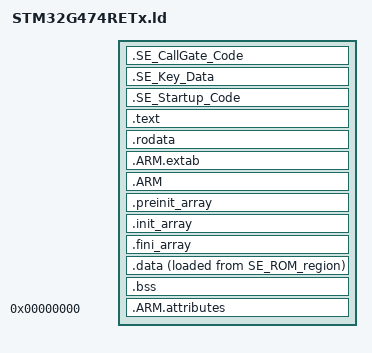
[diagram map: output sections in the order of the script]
/*
*****************************************************************************
**
**  File        : LinkerScript.ld
**
**  Abstract    : Linker script for STM32G474RETx Device with
**                512KByte FLASH, 128KByte RAM
**
**                Set heap size, stack size and stack location according
**                to application requirements.
**
**                Set memory bank area and size if external memory is used.
**
**  Target      : STMicroelectronics STM32
**
**
**  Distribution: The file is distributed as is, without any warranty
**                of any kind.
**
**  (c)Copyright Ac6.
**  You may use this file as-is or modify it according to the needs of your
**  project. Distribution of this file (unmodified or modified) is not
**  permitted. Ac6 permit registered System Workbench for MCU users the
**  rights to distribute the assembled, compiled & linked contents of this
**  file as part of an application binary file, provided that it is built
**  using the System Workbench for MCU toolchain.
**
*****************************************************************************
*/


/* Entry Point */
ENTRY(SE_CallGate)

/* Generate a link error if heap and stack don't fit into RAM */
_Min_Heap_Size = 0;      /* required amount of heap  */
_Min_Stack_Size = 0;     /* specific stack provided inside secured area */

INCLUDE mapping_fwimg.ld
INCLUDE mapping_sbsfu.ld

/* Define output sections */
SECTIONS
{
  .SE_CallGate_Code :
  {
    BYTE(0);           /* dummy byte to keep the callgate at 0x8000204 */
    BYTE(0);           /* dummy byte to keep the callgate at 0x8000204 */
    BYTE(0);           /* dummy byte to keep the callgate at 0x8000204 */
    BYTE(0);           /* dummy byte to keep the callgate at 0x8000204 */
    KEEP(*(.SE_CallGate_Code))
  } > SE_Entry_Secure_ROM_Region

  .SE_Key_Data : { KEEP(*(.SE_Key_Data)) } > SE_Key_region_ROM
  .SE_Startup_Code : { KEEP ( *se_startup.c.obj (.text .text*)) } > SE_Startup_region_ROM
  .text :
  {
    . = ALIGN(8);
    *(.text)           /* .text sections (code) */
    *(.text*)          /* .text* sections (code) */
    *(.glue_7)         /* glue arm to thumb code */
    *(.glue_7t)        /* glue thumb to arm code */
    *(.eh_frame)

    KEEP (*(.init))
    KEEP (*(.fini))

    . = ALIGN(8);
    _etext = .;        /* define a global symbols at end of code */
  } >SE_ROM_region

  /* Constant data goes into FLASH */
  .rodata :
  {
    . = ALIGN(8);
    *(.rodata)         /* .rodata sections (constants, strings, etc.) */
    *(.rodata*)        /* .rodata* sections (constants, strings, etc.) */
    . = ALIGN(8);
  } >SE_ROM_region

  .ARM.extab   :
  {
  . = ALIGN(8);
  *(.ARM.extab* .gnu.linkonce.armextab.*)
  . = ALIGN(8);
  } >SE_ROM_region
  .ARM : {
	. = ALIGN(8);
    __exidx_start = .;
    *(.ARM.exidx*)
    __exidx_end = .;
	. = ALIGN(8);
  } >SE_ROM_region

  .preinit_array     :
  {
	. = ALIGN(8);
    PROVIDE_HIDDEN (__preinit_array_start = .);
    KEEP (*(.preinit_array*))
    PROVIDE_HIDDEN (__preinit_array_end = .);
	. = ALIGN(8);
  } >SE_ROM_region

  .init_array :
  {
	. = ALIGN(8);
    PROVIDE_HIDDEN (__init_array_start = .);
    KEEP (*(SORT(.init_array.*)))
    KEEP (*(.init_array*))
    PROVIDE_HIDDEN (__init_array_end = .);
	. = ALIGN(8);
  } >SE_ROM_region
  .fini_array :
  {
	. = ALIGN(8);
    PROVIDE_HIDDEN (__fini_array_start = .);
    KEEP (*(SORT(.fini_array.*)))
    KEEP (*(.fini_array*))
    PROVIDE_HIDDEN (__fini_array_end = .);
	. = ALIGN(8);
  } >SE_ROM_region

  /* used by the startup to initialize data */
  _sidata = LOADADDR(.data);

  /* Initialized data sections goes into RAM, load LMA copy after code */
  .data :
  {
    . = ALIGN(8);
    _sdata = .;        /* create a global symbol at data start */
    *(.data)           /* .data sections */
    *(.data*)          /* .data* sections */

    . = ALIGN(8);
    _edata = .;        /* define a global symbol at data end */
  } >SE_RAM_region AT>SE_ROM_region


  /* Uninitialized data section */
  . = ALIGN(4);
  .bss :
  {
    /* This is used by the startup in order to initialize the .bss section */
    _sbss = .;         /* define a global symbol at bss start */
    __bss_start__ = _sbss;
    *(.bss)
    *(.bss*)
    *(COMMON)

    . = ALIGN(4);
    _ebss = .;         /* define a global symbol at bss end */
    __bss_end__ = _ebss;
  } >SE_RAM_region

  /* User_heap_stack section, used to check that there is enough RAM left */

  /* Remove information from the standard libraries */
  /DISCARD/ :
  {
    libc.a ( * )
    libm.a ( * )
    libgcc.a ( * )
  }

  .ARM.attributes 0 : { *(.ARM.attributes) }
}


